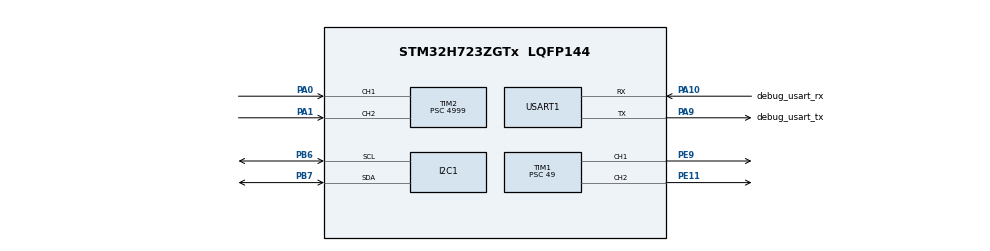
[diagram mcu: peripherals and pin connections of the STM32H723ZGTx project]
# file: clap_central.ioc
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Dma.Request0=USART1_TX
Dma.Request1=USART1_RX
Dma.USART1_RX.1.Direction=DMA_PERIPH_TO_MEMORY
Dma.USART1_RX.1.EventEnable=DISABLE
Dma.USART1_RX.1.FIFOMode=DMA_FIFOMODE_DISABLE
Dma.USART1_RX.1.Instance=DMA1_Stream1
Dma.USART1_RX.1.MemDataAlignment=DMA_MDATAALIGN_BYTE
Dma.USART1_RX.1.MemInc=DMA_MINC_ENABLE
Dma.USART1_RX.1.Mode=DMA_NORMAL
Dma.USART1_RX.1.PeriphDataAlignment=DMA_PDATAALIGN_BYTE
Dma.USART1_RX.1.PeriphInc=DMA_PINC_DISABLE
Dma.USART1_RX.1.Polarity=HAL_DMAMUX_REQ_GEN_RISING
Dma.USART1_RX.1.Priority=DMA_PRIORITY_LOW
Dma.USART1_RX.1.RequestNumber=1
Dma.USART1_RX.1.SignalID=NONE
Dma.USART1_RX.1.SyncEnable=DISABLE
Dma.USART1_RX.1.SyncPolarity=HAL_DMAMUX_SYNC_NO_EVENT
Dma.USART1_RX.1.SyncRequestNumber=1
Dma.USART1_RX.1.SyncSignalID=NONE
Dma.USART1_TX.0.Direction=DMA_MEMORY_TO_PERIPH
Dma.USART1_TX.0.EventEnable=DISABLE
Dma.USART1_TX.0.FIFOMode=DMA_FIFOMODE_DISABLE
Dma.USART1_TX.0.Instance=DMA1_Stream0
Dma.USART1_TX.0.MemDataAlignment=DMA_MDATAALIGN_BYTE
Dma.USART1_TX.0.MemInc=DMA_MINC_ENABLE
Dma.USART1_TX.0.Mode=DMA_NORMAL
Dma.USART1_TX.0.PeriphDataAlignment=DMA_PDATAALIGN_BYTE
Dma.USART1_TX.0.PeriphInc=DMA_PINC_DISABLE
Dma.USART1_TX.0.Polarity=HAL_DMAMUX_REQ_GEN_RISING
Dma.USART1_TX.0.Priority=DMA_PRIORITY_LOW
Dma.USART1_TX.0.RequestNumber=1
Dma.USART1_TX.0.SignalID=NONE
Dma.USART1_TX.0.SyncEnable=DISABLE
Dma.USART1_TX.0.SyncPolarity=HAL_DMAMUX_SYNC_NO_EVENT
Dma.USART1_TX.0.SyncRequestNumber=1
Dma.USART1_TX.0.SyncSignalID=NONE
FREERTOS.BinarySemaphores01=log,Static,logControlBlock
FREERTOS.Tasks01=defaultTask,0,128,StartDefaultTask,Default,NULL,Dynamic,NULL,NULL
I2C1.Timing=0x20A0A3F6
Mcu.Family=STM32H7
Mcu.Name=STM32H723ZGTx
Mcu.Package=LQFP144
NVIC.DMA1_Stream0_IRQn=true\:5\:0\:false\:false\:true\:true\:false\:true\:true
NVIC.DMA1_Stream1_IRQn=true\:5\:0\:false\:false\:true\:true\:false\:true\:true
NVIC.PriorityGroup=NVIC_PRIORITYGROUP_4
NVIC.TIM2_IRQn=true\:5\:0\:false\:false\:true\:true\:true\:true\:true
NVIC.USART1_IRQn=true\:5\:0\:false\:false\:true\:true\:true\:true\:true
PA0.Signal=S_TIM2_CH1_ETR
PA1.Signal=S_TIM2_CH2
PA10.GPIO_Label=debug_usart_rx
PA10.GPIO_Speed=GPIO_SPEED_FREQ_VERY_HIGH
PA10.Mode=Asynchronous
PA10.Signal=USART1_RX
PA13(JTMS/SWDIO).Mode=Serial_Wire
PA13(JTMS/SWDIO).Signal=DEBUG_JTMS-SWDIO
PA14(JTCK/SWCLK).Mode=Serial_Wire
PA14(JTCK/SWCLK).Signal=DEBUG_JTCK-SWCLK
PA9.GPIO_Label=debug_usart_tx
PA9.GPIO_Speed=GPIO_SPEED_FREQ_VERY_HIGH
PA9.Mode=Asynchronous
PA9.Signal=USART1_TX
PB6.Mode=I2C
PB6.Signal=I2C1_SCL
PB7.Mode=I2C
PB7.Signal=I2C1_SDA
PE11.Signal=S_TIM1_CH2
PE9.Signal=S_TIM1_CH1
PH0-OSC_IN.Mode=HSE-External-Oscillator
PH0-OSC_IN.Signal=RCC_OSC_IN
PH1-OSC_OUT.Mode=HSE-External-Oscillator
PH1-OSC_OUT.Signal=RCC_OSC_OUT
ProjectManager.HeapSize=0x200
ProjectManager.StackSize=0x400
ProjectManager.TargetToolchain=MDK-ARM V5.32
RCC.ADCFreq_Value=50390625
RCC.APB1Freq_Value=125000000
RCC.APB2Freq_Value=125000000
RCC.APB3Freq_Value=125000000
RCC.APB4Freq_Value=125000000
RCC.CortexFreq_Value=500000000
RCC.D1PPRE=RCC_APB3_DIV2
RCC.D2PPRE1=RCC_APB1_DIV2
RCC.D2PPRE2=RCC_APB2_DIV2
RCC.D3PPRE=RCC_APB4_DIV2
RCC.DIVM1=10
RCC.DIVN1=200
RCC.DIVP1=1
RCC.HCLKFreq_Value=250000000
RCC.HPRE=RCC_HCLK_DIV2
RCC.PLLSourceVirtual=RCC_PLLSOURCE_HSE
RCC.SYSCLKFreq_VALUE=500000000
RCC.SYSCLKSource=RCC_SYSCLKSOURCE_PLLCLK
RCC.USBFreq_Value=250000000
SH.S_TIM1_CH1.0=TIM1_CH1,PWM Generation1 CH1
SH.S_TIM1_CH2.0=TIM1_CH2,PWM Generation2 CH2
SH.S_TIM2_CH1_ETR.0=TIM2_CH1,Input_Capture1_from_TI1
SH.S_TIM2_CH2.0=TIM2_CH2,Input_Capture2_from_TI2
TIM1.Channel-PWM\ Generation1\ CH1=TIM_CHANNEL_1
TIM1.Channel-PWM\ Generation2\ CH2=TIM_CHANNEL_2
TIM1.Period=499
TIM1.Prescaler=49
TIM2.Channel-Input_Capture1_from_TI1=TIM_CHANNEL_1
TIM2.Channel-Input_Capture2_from_TI2=TIM_CHANNEL_2
TIM2.Period=49999
TIM2.Prescaler=4999
USART1.VirtualMode-Asynchronous=VM_ASYNC
VP_FREERTOS_VS_CMSIS_V1.Mode=CMSIS_V1
board=custom

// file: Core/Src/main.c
/* USER CODE BEGIN Header */
/**
  ******************************************************************************
  * @file           : main.c
  * @brief          : Main program body
  ******************************************************************************
  * @attention
  *
  * Copyright (c) 2025 STMicroelectronics.
  * All rights reserved.
  *
  * This software is licensed under terms that can be found in the LICENSE file
  * in the root directory of this software component.
  * If no LICENSE file comes with this software, it is provided AS-IS.
  *
  ******************************************************************************
  */
/* USER CODE END Header */
#include "main.h"
#include "cmsis_os.h"
#include "dma.h"
#include "i2c.h"
#include "tim.h"
#include "usart.h"
#include "gpio.h"

void SystemClock_Config(void);
void MX_FREERTOS_Init(void);

int main(void)
{

  /* MCU Configuration--------------------------------------------------------*/

  /* Reset of all peripherals, Initializes the Flash interface and the Systick. */
  HAL_Init();

  /* Configure the system clock */
  SystemClock_Config();

  /* Initialize all configured peripherals */
  MX_GPIO_Init();
  MX_DMA_Init();
  MX_USART1_UART_Init();
  MX_TIM1_Init();
  MX_TIM2_Init();
  MX_I2C1_Init();
  /* USER CODE BEGIN 2 */
  bsp_init();
  drv_log_init();
  /* USER CODE END 2 */

  /* Call init function for freertos objects (in freertos.c) */
  MX_FREERTOS_Init();

  /* Start scheduler */
  osKernelStart();
  /* We should never get here as control is now taken by the scheduler */
  /* Infinite loop */
  while (1)
  {

  }
}

void SystemClock_Config(void)
{
  RCC_OscInitTypeDef RCC_OscInitStruct = {0};
  RCC_ClkInitTypeDef RCC_ClkInitStruct = {0};

  /** Supply configuration update enable
  */
  HAL_PWREx_ConfigSupply(PWR_LDO_SUPPLY);

  /** Configure the main internal regulator output voltage
  */
  __HAL_PWR_VOLTAGESCALING_CONFIG(PWR_REGULATOR_VOLTAGE_SCALE0);

  while(!__HAL_PWR_GET_FLAG(PWR_FLAG_VOSRDY)) {}

  /** Initializes the RCC Oscillators according to the specified parameters
  * in the RCC_OscInitTypeDef structure.
  */
  RCC_OscInitStruct.OscillatorType = RCC_OSCILLATORTYPE_HSE;
  RCC_OscInitStruct.HSEState = RCC_HSE_ON;
  RCC_OscInitStruct.PLL.PLLState = RCC_PLL_ON;
  RCC_OscInitStruct.PLL.PLLSource = RCC_PLLSOURCE_HSE;
  RCC_OscInitStruct.PLL.PLLM = 10;
  RCC_OscInitStruct.PLL.PLLN = 200;
  RCC_OscInitStruct.PLL.PLLP = 1;
  RCC_OscInitStruct.PLL.PLLQ = 2;
  RCC_OscInitStruct.PLL.PLLR = 2;
  RCC_OscInitStruct.PLL.PLLRGE = RCC_PLL1VCIRANGE_1;
  RCC_OscInitStruct.PLL.PLLVCOSEL = RCC_PLL1VCOWIDE;
  RCC_OscInitStruct.PLL.PLLFRACN = 0;
  if (HAL_RCC_OscConfig(&RCC_OscInitStruct) != HAL_OK)
  {
    Error_Handler();
  }

  /** Initializes the CPU, AHB and APB buses clocks
  */
  RCC_ClkInitStruct.ClockType = RCC_CLOCKTYPE_HCLK|RCC_CLOCKTYPE_SYSCLK
                              |RCC_CLOCKTYPE_PCLK1|RCC_CLOCKTYPE_PCLK2
                              |RCC_CLOCKTYPE_D3PCLK1|RCC_CLOCKTYPE_D1PCLK1;
  RCC_ClkInitStruct.SYSCLKSource = RCC_SYSCLKSOURCE_PLLCLK;
  RCC_ClkInitStruct.SYSCLKDivider = RCC_SYSCLK_DIV1;
  RCC_ClkInitStruct.AHBCLKDivider = RCC_HCLK_DIV2;
  RCC_ClkInitStruct.APB3CLKDivider = RCC_APB3_DIV2;
  RCC_ClkInitStruct.APB1CLKDivider = RCC_APB1_DIV2;
  RCC_ClkInitStruct.APB2CLKDivider = RCC_APB2_DIV2;
  RCC_ClkInitStruct.APB4CLKDivider = RCC_APB4_DIV2;

  if (HAL_RCC_ClockConfig(&RCC_ClkInitStruct, FLASH_LATENCY_3) != HAL_OK)
  {
    Error_Handler();
  }
}

void Error_Handler(void)
{
  __disable_irq();
  while (1)
  {
  }
}

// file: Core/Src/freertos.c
/* USER CODE BEGIN Header */
/**
  ******************************************************************************
  * File Name          : freertos.c
  * Description        : Code for freertos applications
  ******************************************************************************
  * @attention
  *
  * Copyright (c) 2025 STMicroelectronics.
  * All rights reserved.
  *
  * This software is licensed under terms that can be found in the LICENSE file
  * in the root directory of this software component.
  * If no LICENSE file comes with this software, it is provided AS-IS.
  *
  ******************************************************************************
  */
/* USER CODE END Header */

#include "FreeRTOS.h"
#include "task.h"
#include "main.h"
#include "cmsis_os.h"

osThreadId defaultTaskHandle;
osSemaphoreId logHandle;
osStaticSemaphoreDef_t logControlBlock;

void StartDefaultTask(void const * argument);

void MX_FREERTOS_Init(void); /* (MISRA C 2004 rule 8.1) */

/* GetIdleTaskMemory prototype (linked to static allocation support) */
void vApplicationGetIdleTaskMemory( StaticTask_t **ppxIdleTaskTCBBuffer, StackType_t **ppxIdleTaskStackBuffer, uint32_t *pulIdleTaskStackSize );

/* USER CODE BEGIN GET_IDLE_TASK_MEMORY */
static StaticTask_t xIdleTaskTCBBuffer;
static StackType_t xIdleStack[configMINIMAL_STACK_SIZE];

void vApplicationGetIdleTaskMemory( StaticTask_t **ppxIdleTaskTCBBuffer, StackType_t **ppxIdleTaskStackBuffer, uint32_t *pulIdleTaskStackSize )
{
  *ppxIdleTaskTCBBuffer = &xIdleTaskTCBBuffer;
  *ppxIdleTaskStackBuffer = &xIdleStack[0];
  *pulIdleTaskStackSize = configMINIMAL_STACK_SIZE;
  /* place for user code */
}
/* USER CODE END GET_IDLE_TASK_MEMORY */

void MX_FREERTOS_Init(void) {

  /* Create the semaphores(s) */
  /* definition and creation of log */
  osSemaphoreStaticDef(log, &logControlBlock);
  logHandle = osSemaphoreCreate(osSemaphore(log), 1);

  /* Create the thread(s) */
  /* definition and creation of defaultTask */
  osThreadDef(defaultTask, StartDefaultTask, osPriorityNormal, 0, 128);
  defaultTaskHandle = osThreadCreate(osThread(defaultTask), NULL);

}

void StartDefaultTask(void const * argument)
{
  /* USER CODE BEGIN StartDefaultTask */
  /* Infinite loop */
  static uint8_t cnt=0;
  g_wheel_pwm.start(&g_wheel_pwm,0);
  for(;;)
  {
//    cnt++;
//    if(cnt<100){
//      g_wheel_pwm.set_duty(&g_wheel_pwm,0,cnt *1.0f/100);
//    }else{
//      g_wheel_pwm.set_duty(&g_wheel_pwm,0,0);
//      cnt=0;
//    }
    g_wheel_pwm.set_duty(&g_wheel_pwm,0,0.2f );
    osDelay(1000);
  }
  /* USER CODE END StartDefaultTask */
}
